# ATSAML22G18A register map
Vendor: Microchip Technology; Series: SAML22; File version: 0
CPU: CM0+ r0p0, little endian, MPU, no FPU, VTOR, 2 interrupt priority bits, 26 interrupts
Registers are 32-bit, read-write, reset 0x0 unless marked. A register's access mark holds for its fields unless they carry their own. Offsets are from the block's base; [hi:lo] are bit positions; lines under a group give offsets from that group; {n}, {i} and the like mark numbered series; 'fields as' and 'values as' point back to an identical list.

## PM — Power Manager
Base 0x40000400
0x00 CTRLA 8-bit — Control A
  [2] IORET — I/O Retention
0x01 SLEEPCFG 8-bit reset 0x2 — Sleep Configuration
  [2:0] SLEEPMODE
    2=IDLE (CPU, AHBx, and APBx clocks are OFF); 4=STANDBY (All Clocks are OFF); 5=BACKUP (Only Backup domain is powered ON); 6=OFF (All power domains are powered OFF)
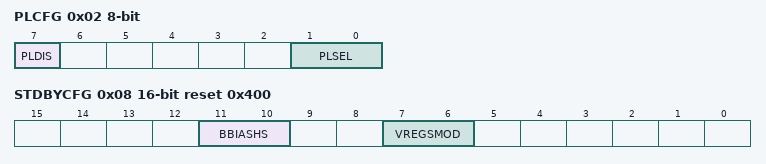
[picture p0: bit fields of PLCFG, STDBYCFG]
0x02 PLCFG 8-bit — Performance Level Configuration
  [7] PLDIS — Performance Level Disable
  [1:0] PLSEL — Performance Level Select
    0=PL0 (Performance Level 0); 1=PL1 (Performance Level 1); 2=PL2 (Performance Level 2)
0x04 INTENCLR 8-bit write-1-clears — Interrupt Enable Clear
  [0] PLRDY — Performance Level Interrupt Enable
0x05 INTENSET 8-bit write-1-sets — Interrupt Enable Set
  [0] PLRDY — Performance Level Ready interrupt Enable
0x06 INTFLAG 8-bit write-1-clears — Interrupt Flag Status and Clear
  [0] PLRDY — Performance Level Ready
0x08 STDBYCFG 16-bit reset 0x400 — Standby Configuration
  [11:10] BBIASHS — Back Bias for HMCRAMCHS
    0=RETBB (Retention Back Biasing mode); 1=STDBYBB (Standby Back Biasing mode); 2=STDBYOFF (Standby OFF mode); 3=OFF (Always OFF mode)
  [7:6] VREGSMOD — Voltage Regulator Standby mode
    0=AUTO (Automatic mode); 1=PERFORMANCE (Performance oriented); 2=LP (Low Power oriented)

## PORT — Port Module
Base 0x41006000
Same registers: PORT_IOBUS 0x60000000
{0x0+0x80*i} GROUP[{i}] (i=0..1) group
  0x00 DIR — Data Direction
  0x04 DIRCLR — Data Direction Clear
  0x08 DIRSET — Data Direction Set
  0x0C DIRTGL — Data Direction Toggle
  0x10 OUT — Data Output Value
  0x14 OUTCLR — Data Output Value Clear
  0x18 OUTSET — Data Output Value Set
  0x1C OUTTGL — Data Output Value Toggle
  0x20 IN ro — Data Input Value
  0x24 CTRL — Control
    [31:0] SAMPLING — Input Sampling Mode
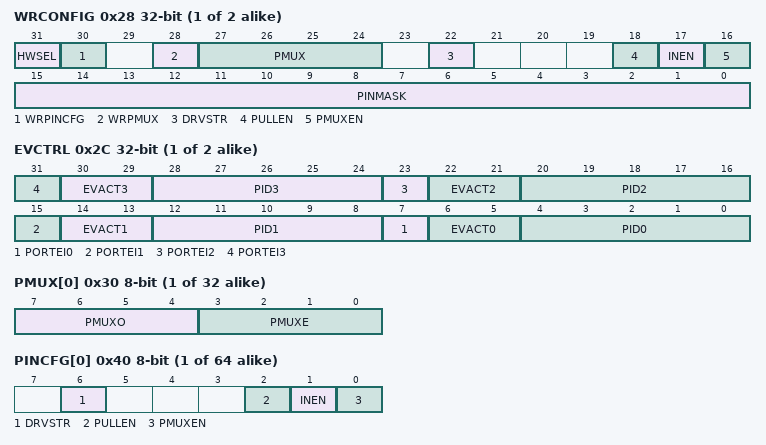
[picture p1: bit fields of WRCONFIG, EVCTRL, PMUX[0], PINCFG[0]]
  0x28 WRCONFIG wo — Write Configuration
    [31] HWSEL — Half-Word Select
    [30] WRPINCFG — Write PINCFG Registers
    [28] WRPMUX — Write PMUX Registers
    [27:24] PMUX — Peripheral Multiplexing Template
    [22] DRVSTR — Output Driver Strength Selection
    [18] PULLEN — Pull Enable
    [17] INEN — Input Enable
    [16] PMUXEN — Select Peripheral Multiplexer
    [15:0] PINMASK — Pin Mask for Multiple Pin Configuration
  0x2C EVCTRL — Event Input Control
    [8n+7] PORTEI{n} (n=0..3) — Port Event Enable Input {n}
    [30:29] EVACT3 — Port Event Action 3
    [8n+4:8n] PID{n} (n=0..3) — Port Event Pin Identifier {n}
    [22:21] EVACT2 — Port Event Action 2
    [14:13] EVACT1 — Port Event Action 1
    [6:5] EVACT0 — Port Event Action 0
      0=OUT (Event output to pin); 1=SET (Set output register of pin on event); 2=CLR (Clear output register of pin on event); 3=TGL (Toggle output register of pin on event)
  {0x30+j} PMUX[{j}] (j=0..15) 8-bit — Peripheral Multiplexing n
    [7:4] PMUXO — Peripheral Multiplexing for Odd-Numbered Pin
      0=A (Peripheral function A selected); 1=B (Peripheral function B selected); 2=C (Peripheral function C selected); 3=D (Peripheral function D selected); 4=E (Peripheral function E selected); 5=F (Peripheral function F selected); 6=G (Peripheral function G selected); 7=H (Peripheral function H selected); 8=I (Peripheral function I selected)
    [3:0] PMUXE — Peripheral Multiplexing for Even-Numbered Pin
      values as PMUXO
  {0x40+j} PINCFG[{j}] (j=0..31) 8-bit — Pin Configuration n
    [6] DRVSTR — Output Driver Strength Selection
    [2] PULLEN — Pull Enable
    [1] INEN — Input Enable
    [0] PMUXEN — Select Peripheral Multiplexer

## RSTC — Reset Controller
Base 0x40000C00
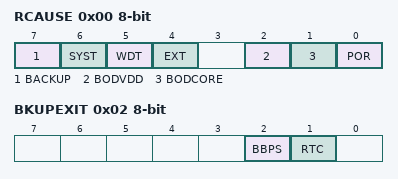
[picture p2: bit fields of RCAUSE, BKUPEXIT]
0x00 RCAUSE 8-bit ro — Reset Cause
  [7] BACKUP — Backup Reset
  [6] SYST — System Reset Request
  [5] WDT — Watchdog Reset
  [4] EXT — External Reset
  [2] BODVDD — Brown Out VDD Detector Reset
  [1] BODCORE — Brown Out CORE Detector Reset
  [0] POR — Power On Reset
0x02 BKUPEXIT 8-bit ro — Backup Exit Source
  [2] BBPS — Battery Backup Power Switch
  [1] RTC — Real Timer Counter Interrupt

## Notices in the file
Copyright (c) 2026 Microchip Technology Inc.
SPDX-License-Identifier: Apache-2.0
Licensed under the Apache License, Version 2.0 (the "License");
you may not use this file except in compliance with the License.
You may obtain a copy of the License at
http://www.apache.org/licenses/LICENSE-2.0
Unless required by applicable law or agreed to in writing, software
distributed under the License is distributed on an "AS IS" BASIS,
WITHOUT WARRANTIES OR CONDITIONS OF ANY KIND, either express or implied.
See the License for the specific language governing permissions and
limitations under the License.
